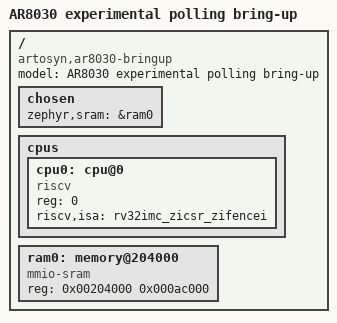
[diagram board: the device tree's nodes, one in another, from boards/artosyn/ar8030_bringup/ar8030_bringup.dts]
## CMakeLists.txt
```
cmake_minimum_required(VERSION 3.20.0)
list(APPEND BOARD_ROOT ${CMAKE_CURRENT_SOURCE_DIR})
list(APPEND SOC_ROOT ${CMAKE_CURRENT_SOURCE_DIR})
list(APPEND DTS_ROOT ${CMAKE_CURRENT_SOURCE_DIR})
if(BOARD MATCHES "^ar8030_bringup")
  list(APPEND EXTRA_CONF_FILE ${CMAKE_CURRENT_SOURCE_DIR}/boards/ar8030_bringup.conf)
endif()
find_package(Zephyr REQUIRED HINTS $ENV{ZEPHYR_BASE})
project(ar8030_zephyr)
target_sources(app PRIVATE src/main.c src/frame.c src/dispatch.c)
if(CONFIG_SOC_AR8030_BRINGUP)
  target_sources(app PRIVATE src/transport_storage.c)
  target_sources(app PRIVATE src/transport.c src/sdio_device.c src/usb_device.c src/rf_device.c src/mac.c src/dev.c src/binding.c src/dev_tx.c src/dev_mcs.c src/ap.c src/fch_monitor.c src/channel_monitor.c src/socket_rx.c src/event.c src/boot.c src/json.c src/config.c src/power_config.c)
  target_sources(app PRIVATE src/power.c src/power_control.c src/flash.c src/flash_spi.c src/sfdp.c src/factory.c src/factory_device.c src/ap_time.c src/ap_hop.c src/pwr_auto.c src/dev_width.c src/frame_stamp.c src/command.c src/scan.c src/scan_scores.c src/tune.c src/phy_control.c src/phy_receive.c)
  target_sources(app PRIVATE src/tx_mcs.c src/interleaver.c src/tx_irq.c)
  target_sources(app PRIVATE src/telemetry.c src/data_framing.c src/data_event.c)
  target_compile_definitions(app PRIVATE AR_SDIO_STOCK_MEMORY_ATTRIBUTES=1)
  set(AR8030_BOOT_PROFILE_SOURCE "" CACHE FILEPATH "Explicit private generated board profile source")
  if(AR8030_BOOT_PROFILE_SOURCE)
    if(NOT EXISTS "${AR8030_BOOT_PROFILE_SOURCE}")
      message(FATAL_ERROR "Requested private boot profile source does not exist")
    endif()
    target_sources(app PRIVATE "${AR8030_BOOT_PROFILE_SOURCE}")
    target_compile_definitions(app PRIVATE AR_BOOT_EMBEDDED=1)
    # A profile may include files kept next to it.
    get_filename_component(AR8030_BOOT_PROFILE_DIR "${AR8030_BOOT_PROFILE_SOURCE}" DIRECTORY)
    target_include_directories(app PRIVATE "${AR8030_BOOT_PROFILE_DIR}")
  endif()
endif()
target_include_directories(app PRIVATE include)
```

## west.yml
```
manifest:
  version: "1.2"
  projects:
    - name: zephyr
      url: https://github.com/zephyrproject-rtos/zephyr
      revision: 3568e1b6d5cdd51a6b964a2a1d6d29200fea2056
      import: true
  self:
    path: ar8030-firmware
```

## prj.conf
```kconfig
CONFIG_SERIAL=y
CONFIG_CONSOLE=n
CONFIG_UART_CONSOLE=n
CONFIG_PRINTK=n
CONFIG_BOOT_BANNER=n
CONFIG_LOG=n
CONFIG_MAIN_STACK_SIZE=4096
CONFIG_ASSERT=y
```

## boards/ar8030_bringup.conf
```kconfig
CONFIG_SERIAL=n
CONFIG_SOC_RESET_HOOK=y
# Aligned RAM copies must not monopolize cooperative RF/SDIO service.
# Zephyr's larger string routines retain byte access for differing alignment.
CONFIG_MINIMAL_LIBC_OPTIMIZE_STRING_FOR_SIZE=n
```

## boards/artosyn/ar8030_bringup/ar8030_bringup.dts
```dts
/* SPDX-License-Identifier: MIT */
/dts-v1/;
/ {
	model = "AR8030 experimental polling bring-up";
	compatible = "artosyn,ar8030-bringup";
	#address-cells = <1>;
	#size-cells = <1>;
	chosen {
		zephyr,sram = &ram0;
	};
	cpus {
		#address-cells = <1>;
		#size-cells = <0>;
		cpu0: cpu@0 {
			device_type = "cpu";
			compatible = "riscv";
			reg = <0>;
			riscv,isa = "rv32imc_zicsr_zifencei";
			status = "okay";
		};
	};
	/* Measured main load address; upper bound keeps the stock header/stack clear. */
	ram0: memory@204000 {
		device_type = "memory";
		compatible = "mmio-sram";
		reg = <0x00204000 0x000ac000>;
	};
	/* 0x0a110000 is the measured baseband/RF page, not a UART. Physical
	 * console MMIO and pin routing remain unresolved; transport is SDIO. */
};
```

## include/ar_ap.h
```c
/* SPDX-License-Identifier: MIT */
#ifndef AR_AP_H
#define AR_AP_H
#include <stddef.h>
#include <stdint.h>

/* AP (transmitter) link control, mode 0, one ground in slot 0: what the AP
 * broadcasts and how it logs a ground in. Learned from what a stock 18.21.10
 * AP sends (captured by an Open8030 DEV) and from what the DEV checks
 * (dev.c): no hardware here, the radio integration feeds it and sends what
 * it builds.
 *
 * Idle: a full control (39 bytes) in every packet: slot bitmap 1, slot 0
 * available (record 0x0001), extension 2 the grounds it serves, extension 3
 * one status byte. A ground answers with a state-1 report (slot 8). Login: the
 * full control carries slot 0 as `token << 8 | 5` (AP state 2) and an
 * extension-0 record [token, value, ground identity, sync 0]. The ground
 * acknowledges with port-0 command 4 and reports state 2 in slot 0: from then
 * on every packet carries the six-byte compact control [check, sequence, token,
 * 2, status, 0]. Reports stopping for `timeout_ms` drop the ground; the next
 * login uses a new token, so a ground still locked to the old one lets go. */

#define AR_AP_MAX_GROUNDS 8
/* A login not acknowledged within this (the ground keeps reporting state 1,
 * or never acknowledges) is dropped, so the slot is offered again. A login
 * takes a few frames; two seconds is hundreds. */
#define AR_AP_LOGIN_TIMEOUT_MS 2000
struct ar_ap_config {
	uint8_t local[4];                       /* the AP's own identity */
	uint8_t grounds[AR_AP_MAX_GROUNDS][4];  /* grounds it serves, extension 2 */
	uint8_t ground_count;
	uint8_t channel;                        /* index in the channel list, both directions */
	uint8_t status;                         /* extension 3 and compact byte 4 (stock 0x50) */
	uint8_t login_value;                    /* login record byte 1 (stock 0x0f) */
	uint16_t timeout_ms;                    /* no report for this long: ground gone */
	uint8_t pairing;                        /* binding: slot 0 offered for pairing, any ground served */
};
enum ar_ap_state { AR_AP_IDLE = 0, AR_AP_LOGIN = 1, AR_AP_CONNECTED = 2 };
struct ar_ap {
	struct ar_ap_config config;
	uint8_t state, token, sequence;
	uint8_t ground[4];                      /* the ground being logged in / connected */
	uint8_t sync[4];
	uint32_t last_report_ms, login_ms;
	uint32_t reports, bad_reports, foreign_reports, logins, connects, drops, acks, bad_acks;
	uint32_t login_timeouts;                /* logins dropped unacknowledged */
	uint8_t report_state, report_slot, report_channel, report_value;
	uint8_t bandwidth_request;              /* last port-0 command 9 code + 1, 0 = none */
};
void ar_ap_init(struct ar_ap *ap, const struct ar_ap_config *config, uint8_t first_token);
/* Change what the idle broadcast offers (grounds, channel, pairing). A ground
 * already connected stays unless it is no longer served. */
void ar_ap_configure(struct ar_ap *ap, const struct ar_ap_config *config);
/* The outband for the next packet. Returns its length, or 0 if `capacity`
 * is too small. Full form while idle and logging in, compact once connected. */
size_t ar_ap_control(struct ar_ap *ap, uint8_t *out, size_t capacity);
/* A ground's uplink outband (its 16-byte report). Returns 1 if the link state
 * changed, 0 if not, negative if the report is not valid. */
int ar_ap_report(struct ar_ap *ap, const uint8_t *outband, size_t length, uint32_t now_ms);
/* One port-0 command envelope from the connected or logging-in ground. */
void ar_ap_command(struct ar_ap *ap, const uint8_t *envelope, size_t length, uint32_t now_ms);
/* Time-outs. Returns 1 if the ground was dropped. */
int ar_ap_poll(struct ar_ap *ap, uint32_t now_ms);
/* The lookup checksum (ar_mac_crc8_step) over `length` bytes, the byte at
 * index `zero` taken as 0: the full form's own check byte (index 2). Pass an
 * index past the end to take every byte. */
uint8_t ar_ap_checksum(const uint8_t *data, size_t length, size_t zero);
#endif
```

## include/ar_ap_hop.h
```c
/* SPDX-License-Identifier: MIT */
#ifndef AR_AP_HOP_H
#define AR_AP_HOP_H
#include <stdint.h>

/* An AP's own channel choice (stock bb_phy_chan_policy_pre_proc), the pure
 * part: the retransmission measure and the hop decision. The configuration
 * is stock's bb_load_channel: channel.hop_para tiers {retx_cnt, power_diff
 * dB}, hop_ex.blind_hop {at_err_cnt, duration ms}, init_chan -1 (the start
 * channel picked by measurement) and channel.mode "auto" (hopping on from
 * the start; a host's SET 5 turns it on and off later). */
#define AR_HOP_TIERS 5
struct ar_hop_config {
	uint16_t blind_ms;
	uint8_t blind_errors, tier_count;
	uint8_t tiers[AR_HOP_TIERS][2];
	uint8_t measure_start, auto_start;
};
/* Each frame's broadcast HARQ request: whether a block went again. The
 * measure is the longer of the run of such frames (less one) and their
 * count in the last 16. */
struct ar_hop_measure { uint16_t bits; uint8_t run, newest; };
void ar_hop_measure_reset(struct ar_hop_measure *measure);
/* The frame's request IDs (0..15; second 255 when there is none). Returns
 * 1 when one of them is not one of the next two new blocks. */
unsigned ar_hop_measure_feed(struct ar_hop_measure *measure, uint8_t first, uint8_t second);
unsigned ar_hop_measure_value(const struct ar_hop_measure *measure);
enum ar_hop_decision { AR_HOP_STAY = 0, AR_HOP_BY_LEVEL = 1, AR_HOP_BLIND = 2 };
/* Levels are the scan's (dBm, lower is quieter): ours, and the quietest
 * other work channel's. Below blind_errors, or within blind_ms of the last
 * blind hop: the first tier whose count is not below the measure needs the
 * best channel that many dB quieter; past every tier, any best channel. At
 * blind_errors and more otherwise: a blind hop (to the best channel, else
 * the caller's next one), and *last_blind_ms takes now_ms (0: never). */
enum ar_hop_decision ar_hop_decide(const struct ar_hop_config *config, unsigned measure,
	int own_known, int32_t own_level, int best_known, int32_t best_level,
	uint32_t now_ms, uint32_t *last_blind_ms);
#endif
```

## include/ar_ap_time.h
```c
/* SPDX-License-Identifier: MIT */
#ifndef AR_AP_TIME_H
#define AR_AP_TIME_H
#include <stdint.h>

/* DEV-side estimate of the AP's wrapping 32-bit millisecond clock. */
struct ar_ap_time {
	uint32_t offset_ms;
	uint8_t valid;
};
void ar_ap_time_reset(struct ar_ap_time *time);
/* Caller has validated the seven-byte PHY checksum, command7 and length4.
 * Use the same continuous local clock for reception and getter calls. */
void ar_ap_time_receive(struct ar_ap_time *time, const uint8_t control[7], uint32_t local_ms);
/* Original GET_AP_TIME returns success with UINT32_MAX until synchronized. */
uint32_t ar_ap_time_get(const struct ar_ap_time *time, uint32_t local_ms);
#endif
```

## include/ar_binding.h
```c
/* SPDX-License-Identifier: MIT */
#ifndef AR_BINDING_H
#define AR_BINDING_H
#include <stddef.h>
#include <stdint.h>

/* DEV pairing control (0x02000002) and result (0x01000001).
 * Persistence belongs to the Linux backend. A result is published only after
 * radio login completes, never merely upon seeing an available AP. */
struct ar_binding {
	uint8_t enabled, complete, slot, peer[4], skip[3][4], sample[16];
};
int ar_binding_set(struct ar_binding *binding, const uint8_t *data, size_t length);
void ar_binding_complete(struct ar_binding *binding, unsigned slot,
	const uint8_t peer[4], const uint8_t sample[16]);
int ar_binding_result(const struct ar_binding *binding, uint8_t output[164]);
#endif
```

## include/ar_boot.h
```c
/* SPDX-License-Identifier: MIT */
#ifndef AR_BOOT_H
#define AR_BOOT_H
#include <stddef.h>
#include <stdint.h>
#include "ar_flash_spi.h"

/* Explicit board facts, not original firmware code or a generic board profile. */
struct ar_boot_profile {
	const uint8_t *defaults, *pins, *plan;
	size_t defaults_length, pins_length, plan_length;
	const uint8_t *fch_keys;
	size_t keys_length;
	const struct ar_flash_part *flash_parts;
	size_t flash_part_count;
	/* I/O voltage domains to select (GPIO+0 bit 1 bank 2, bit 2 bank 3);
	 * 0 = those of the banks the pin records use. One tested air
	 * board selects bank 3's only. */
	uint8_t io_domains;
};
enum ar_boot_stage {
	AR_BOOT_IDLE, AR_BOOT_VALIDATE, AR_BOOT_PROBE, AR_BOOT_PINS,
	AR_BOOT_DEFAULTS, AR_BOOT_CALIBRATE, AR_BOOT_PSRAM, AR_BOOT_PREPARE,
	AR_BOOT_READY, AR_BOOT_FACTORY
};
struct ar_boot_info {
	uint32_t version, stage;
	int32_t error;
	uint32_t default_bytes, rf_bound_ms, config_bytes, config_crc32c, identity_source;
	uint32_t factory_stage;
	int32_t factory_error;
	uint32_t flash_capacity, factory_partition, power_source;
	int32_t power_offsets[2];
	uint32_t flash_id[2], flash_source;
};
/* Initializes with RF held; only the real backend's candidate command starts RF.
 * Stops at the first failure. It does not recover/restart an active session. */
int ar_boot_prepare(const struct ar_boot_profile *profile);
/* Normal loader region, bounded at the next executable segment. */
int ar_boot_prepare_loader(const struct ar_boot_profile *profile, const char *json, size_t capacity);
const struct ar_boot_info *ar_boot_information(void);
#ifdef AR_BOOT_EMBEDDED
extern const struct ar_boot_profile ar_boot_embedded_profile;
#endif
#endif
```

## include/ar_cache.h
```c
/* SPDX-License-Identifier: MIT */
#ifndef AR_CACHE_H
#define AR_CACHE_H
#include <stddef.h>
#include <stdint.h>
/* T-Head data-cache maintenance by physical address, 32-byte lines, as the
 * stock firmware's 0x217948 (invalidate), 0x21796e (clean) and 0x217996
 * (clean+invalidate) helpers do, fences before and after. The attribute
 * table at 0xeffff000 makes RAM 0x200000..0x300000 the only cached region,
 * so only buffers the baseband, USB or SDIO engines read or write need this:
 * clean before an engine reads a CPU-written buffer, invalidate before the
 * CPU reads an engine-written one (and flush before arming such a buffer so
 * no dirty line lands on the engine's data). */
#define AR_CACHE_LINE 32u
#if defined(__riscv)
#define AR_CACHE_OP(insn, address) do { \
	register uintptr_t ar_cache_a5 __asm__("a5") = (address); \
	__asm__ volatile(".word " insn :: "r"(ar_cache_a5) : "memory"); } while (0)
static inline void ar_cache_range(const void *data, size_t length, unsigned op)
{
	uintptr_t address = (uintptr_t)data & ~(uintptr_t)(AR_CACHE_LINE - 1);
	uintptr_t end = ((uintptr_t)data + length + AR_CACHE_LINE - 1) & ~(uintptr_t)(AR_CACHE_LINE - 1);
	__asm__ volatile("fence" ::: "memory");
	for (; address < end; address += AR_CACHE_LINE) {
		if (op == 0) { AR_CACHE_OP("0x02a7800b", address); }      /* th.dcache.ipa a5 */
		else if (op == 1) { AR_CACHE_OP("0x0297800b", address); } /* th.dcache.cpa a5 */
		else { AR_CACHE_OP("0x02b7800b", address); }              /* th.dcache.cipa a5 */
	}
	__asm__ volatile("fence\n\tfence" ::: "memory");
}
#else
/* Host builds (native tests): no data cache to maintain. */
static inline void ar_cache_range(const void *data, size_t length, unsigned op) { (void)data; (void)length; (void)op; }
#endif
static inline void ar_cache_invalidate(const void *data, size_t length) { ar_cache_range(data, length, 0); }
static inline void ar_cache_clean(const void *data, size_t length) { ar_cache_range(data, length, 1); }
static inline void ar_cache_flush(const void *data, size_t length) { ar_cache_range(data, length, 2); }
#endif
```

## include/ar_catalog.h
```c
/* SPDX-License-Identifier: MIT */
#ifndef AR_CATALOG_H
#define AR_CATALOG_H
#include <stddef.h>
#include <stdint.h>

/* Native views of catalog state, not original firmware structure declarations.
 * Rows use the same frequency/enable/band fields as ar_scan. Groups are separate
 * low-nibble values. The full configured frequencies and processed scan scores
 * must be supplied independently when serializing channel information. */
enum ar_catalog_action {
	AR_CATALOG_MODE = 1,
	AR_CATALOG_CHANNEL,
	AR_CATALOG_AP_LOCK,
	AR_CATALOG_AP_TUNE,
	AR_CATALOG_AP_UNLOCK,
	AR_CATALOG_RESET_SCAN,
};
struct ar_catalog_selection {
	uint16_t channel, ap_channel;
	uint8_t role, policy_flags, ap_state, group_count, current_group;
	uint16_t best_group[16];
};
/* MODE/CHANNEL correspond to the channel-policy helper with selector 1/user12.
 * AP_TUNE uses user8/TX. Callbacks run synchronously and may update selection;
 * current_group is read from the resulting channel after the policy callback.
 * Callbacks must preserve the structural validity of the supplied state.
 * RESET_SCAN represents the original auxiliary-scan reset helper, not a no-op.
 * Lock callbacks must be paired by the caller's implementation. */
typedef void (*ar_catalog_effect)(enum ar_catalog_action action, uint32_t value,
	void *context);

int ar_catalog_information(const uint32_t *frequencies, const int32_t *scores,
	size_t count, uint8_t mode, uint8_t selected, uint8_t working,
	uint8_t output[1028]);
int ar_catalog_enabled(const uint32_t *rows, size_t count, uint8_t output[129]);
/* indices contains the list only, without its count byte. A count outside
 * 1..128 or a NULL list returns original -6. Native preflight validation uses
 * -22 and leaves state untouched. Invalid/forbidden indices are skipped, but
 * the original fallback/AP request still uses indices[0], even if it was
 * skipped. The callback must perform the policy helper's own validation. */
int ar_catalog_set_work(uint32_t *rows, const uint8_t *groups, size_t count,
	uint8_t band_mask, const uint8_t *indices, size_t length,
	struct ar_catalog_selection *selection, ar_catalog_effect effect, void *context);
#endif
```

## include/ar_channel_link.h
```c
/* SPDX-License-Identifier: MIT */
#ifndef AR_CHANNEL_LINK_H
#define AR_CHANNEL_LINK_H
#include "ar_channel_work.h"

/* Native state views; no original object offsets or ABI are implied. */
struct ar_channel_dev_channels { uint16_t broadcast_tx, broadcast_rx, slot_tx, slot_rx; };
struct ar_channel_ap_channels {
	uint16_t broadcast_rx, broadcast_tx, receive, slot_tx[8];
};
struct ar_channel_link {
	struct ar_channel_dev_channels dev;
	struct ar_channel_ap_channels ap;
	uint16_t auxiliary_channel, hold_mask;
	int32_t ignore_once;
	uint8_t role, mode, slot, channel_flags, current_band;
	uint8_t auxiliary_flags, auxiliary_user, auxiliary_direction;
	uint8_t monitor_flags, monitor_threshold, monitor_channel, monitor_deadline;
};
enum ar_channel_link_lock { AR_CHANNEL_LINK_NODE, AR_CHANNEL_LINK_AUXILIARY };
struct ar_channel_link_ops {
	void (*lock)(enum ar_channel_link_lock which, void *context);
	void (*unlock)(enum ar_channel_link_lock which, void *context);
	ar_channel_field field;
	int (*tune)(unsigned user, unsigned direction, uint16_t channel, void *context);
	int (*notify)(unsigned event, const uint8_t payload[4], void *context);
	ar_channel_post post;
};
/* PHY command4 callback. outgoing is the original callback direction argument;
 * any nonzero value selects outgoing handling. RX=1, TX=0 for tune operations.
 * State changes precede their corresponding effects, even if tune/notify/post
 * returns an error. A pending monitor suppresses immediate completion.
 * Cross-band preparation is included; actual tuning and completion monitoring
 * belong to the caller. rows uses the ar_scan/catalog band encoding.
 * Return0 means handled, not successful tuning. Native -22 rejects malformed
 * storage/length/header and unsafe cross-band lookup before any effect. */
int ar_channel_link_apply(struct ar_channel_link *state,
	const uint32_t *rows, size_t count, uint32_t outgoing,
	const uint8_t *payload, size_t length,
	const struct ar_channel_link_ops *ops, void *context);
#endif
```

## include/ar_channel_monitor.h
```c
/* SPDX-License-Identifier: MIT */
#ifndef AR_CHANNEL_MONITOR_H
#define AR_CHANNEL_MONITOR_H
#include "ar_channel_work.h"

struct ar_channel_monitor_user {
	uint8_t flags, threshold, missed, channel, deadline;
};
struct ar_channel_monitor {
	struct ar_channel_monitor_user users[10];
	uint32_t hop_ms[2];
	uint16_t hold_mask;
	uint8_t successes, unlocks, role, mode, policy_flags, group, band;
	uint8_t reset_suppressed, reset_mode;
};
struct ar_channel_monitor_ops {
	void (*reset)(unsigned per_user, unsigned user, void *context);
	ar_channel_field field;
	ar_channel_post post;
	/* Optional loss callback may update the user before timer cleanup. */
	void (*lost)(unsigned user, struct ar_channel_monitor_user *state, void *context);
	uint32_t (*current)(unsigned selector, void *context);
	uint32_t (*preferred)(unsigned group, unsigned channel, void *context);
	int (*next)(uint16_t *channel, unsigned group, void *context);
	int (*last)(uint16_t *channel, unsigned group, void *context);
	void (*hop)(uint16_t channel, void *context);
	uint32_t (*now_ms)(void *context);
};
/* Serialized monitor state transitions. Flags retain original enabled/locked,
 * forced, two-bit streak, band-hold and pending-completion bits. Success and
 * unlock counters are shared by all users. first[] supplies each group's first
 * channel for blind hopping. Native storage errors return -22 before effects.
 * Hardware callbacks, timer scheduling and diagnostic history collection are
 * caller responsibilities. Runtime mode0 user8 uses observation/loss handling;
 * channel-change completion and hopping integration remain pending. */
int ar_channel_monitor_observe(struct ar_channel_monitor *state, unsigned user,
	uint32_t locked, const uint16_t *first, size_t count,
	const struct ar_channel_monitor_ops *ops, void *context);
int ar_channel_monitor_tick(struct ar_channel_monitor *state,
	const struct ar_channel_monitor_ops *ops, void *context);
#endif
```

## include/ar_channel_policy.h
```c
/* SPDX-License-Identifier: MIT */
#ifndef AR_CHANNEL_POLICY_H
#define AR_CHANNEL_POLICY_H
#include "ar_channel_work.h"

/* Native state for selector1 of the original channel-policy entry point.
 * Catalog and score storage are supplied by the caller. Base channels only;
 * current/auxiliary channel must address allocated entries. */
struct ar_channel_policy {
	struct ar_channel_request_state request;
	/* transmit_channel is the DEV slot TX channel or AP broadcast TX channel. */
	uint16_t channel, auxiliary_channel, transmit_channel, backups[4];
	uint8_t mode, band, group, auxiliary_flags, role, slots;
};
enum ar_channel_policy_lock { AR_CHANNEL_POLICY_LOCK, AR_CHANNEL_AUX_LOCK };
struct ar_channel_policy_ops {
	void (*lock)(enum ar_channel_policy_lock which, void *context);
	void (*unlock)(enum ar_channel_policy_lock which, void *context);
	/* PHY command8/TTL8, four bytes. Native clears the original unspecified
	 * high nibble of byte3. Return value controls leaving hopping mode. */
	int (*phy)(unsigned command, unsigned ttl, const uint8_t *payload,
		size_t length, void *context);
	/* Internal port0 command10, eight bytes. DEV sends to slot0; AP sends
	 * to each enabled slot. Sending failure does not suppress the timer. */
	int (*control)(unsigned slot, unsigned command, const uint8_t *payload,
		size_t length, void *context);
	void (*timer)(uint32_t milliseconds, void *context);
	ar_channel_post post;
};
/* Optional mode/channel pointers preserve the original absent-argument
 * distinction. A full 32-bit channel request is compared with the current
 * channel before truncation to16 bits for posting. Return0 is policy acceptance,
 * not completed tuning; the original ignores the queue's posting failure.
 * Native -22 rejects invalid storage/callbacks before locking or mutation.
 * Caller owns synchronization outside the specified lock/unlock operations;
 * callbacks must preserve valid state and storage. */
int ar_channel_policy_set(struct ar_channel_policy *state,
	const uint32_t *rows, const uint8_t *groups, const int32_t *scores,
	size_t count, const uint8_t *mode, const uint32_t *channel,
	const struct ar_channel_policy_ops *ops, void *context);
#endif
```

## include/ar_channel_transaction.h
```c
/* SPDX-License-Identifier: MIT */
#ifndef AR_CHANNEL_TRANSACTION_H
#define AR_CHANNEL_TRANSACTION_H
#include "ar_channel_policy.h"

/* Native views of the link's current channel state and completion histories;
 * these are not original object layouts. */
struct ar_channel_route {
	uint16_t dev_receive, ap_broadcast_transmit;
	uint8_t role, slot, mode, channel_flags, relay;
};
struct ar_channel_histories {
	uint16_t marker;
	/* Optional pointers to the individual counter bytes, not object bases. */
	uint8_t *first[10], *second[8];
};
enum ar_channel_transaction_lock {
	AR_CHANNEL_TRANSACTION_POLICY, AR_CHANNEL_TRANSACTION_DEV, AR_CHANNEL_TRANSACTION_AP
};
struct ar_channel_transaction_ops {
	void (*lock)(enum ar_channel_transaction_lock which, void *context);
	void (*unlock)(enum ar_channel_transaction_lock which, void *context);
	int (*phy)(unsigned command, unsigned ttl, const uint8_t *payload,
		size_t length, void *context);
	ar_channel_post post;
};
/* Link message0x108: send command4/TTL16 with a three-byte channel request.
 * An already-selected DEV channel or selector0 AP broadcast channel only locks
 * and unlocks. Any enqueue failure posts a failed PHY completion (message109),
 * after releasing the link lock. Native clears unwritten completion padding.
 * Return0 means handled, not channel-change success; native validation is -22. */
int ar_channel_route_request(const struct ar_channel_route *route,
	uint32_t selector, uint16_t channel,
	const struct ar_channel_transaction_ops *ops, void *context);
/* PHY message0x109: selector1 commits only a matching pending full16-bit
 * channel. Failure with error0 stages rollback; posting failure leaves it
 * pending. Other selectors clear broadcast pending state only on a matching
 * success. Inflight flags control counter resets; selector1 also clears the
 * complete 16-bit history marker. Band/group lookup uses the channel low byte.
 * This does not tune hardware or establish peer acknowledgement semantics.
 * Native validation leaves state untouched. Callbacks must preserve storage. */
int ar_channel_complete(struct ar_channel_policy *state,
	struct ar_channel_histories *histories, const uint32_t *rows,
	const uint8_t *groups, size_t count, uint32_t success, uint32_t selector,
	uint16_t channel, uint32_t error,
	const struct ar_channel_transaction_ops *ops, void *context);
#endif
```

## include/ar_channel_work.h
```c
/* SPDX-License-Identifier: MIT */
#ifndef AR_CHANNEL_WORK_H
#define AR_CHANNEL_WORK_H
#include <stddef.h>
#include <stdint.h>

/* Native representations, not original firmware structures or wire layouts. */
struct ar_channel_candidate { uint16_t channel; int16_t score; };
/* Rank up to four enabled channels by the signed low 16 bits of their score.
 * Group 3 is a wildcard; ties retain catalog order. If no channel qualifies,
 * return the current channel even if it is disabled or in a different group.
 * Returns 1..4, or native -22 for invalid storage/current/count (1..128).
 * Unused entries contain channel255/score0. */
int ar_channel_candidates(const uint32_t *rows, const uint8_t *groups,
	const int32_t *scores, size_t count, uint8_t group, uint16_t current,
	struct ar_channel_candidate output[4]);

struct ar_channel_request_state {
	uint16_t pending_channel;
	uint8_t broadcast_channel, flags;
};
/* Post destination1/message0x108/timeoutUINT32_MAX. The 8-byte payload contains
 * LE32 selector and LE16 channel; the two original uninitialized padding bytes
 * are deliberately zeroed. The callback observes pending state already set.
 * Return0 indicates posting success only, not completed tuning. */
typedef int (*ar_channel_post)(uint32_t destination, uint32_t message,
	const uint8_t *payload, size_t length, uint32_t timeout, void *context);
int ar_channel_request(struct ar_channel_request_state *state,
	uint32_t selector, uint16_t channel, ar_channel_post post, void *context);

/* Separate auxiliary scan state, not the ten-sample noise-score histories.
 * Record bytes remain opaque until their consumers have been compared. */
struct ar_channel_scan_state {
	uint16_t group_counts[6], channel_counts[128];
	uint8_t records[128][14], marks[128], winners[6], best_group, active;
};
typedef void (*ar_channel_field)(uint32_t field, uint32_t value, void *context);
/* Clears counts first, writes field0x08080f01=1 twice, then clears the other
 * state. Preserve this ordering; the two identical writes are intentional.
 * Native -22 for a missing state/writer, with no side effects. */
int ar_channel_scan_reset(struct ar_channel_scan_state *state,
	ar_channel_field write, void *context);
#endif
```
